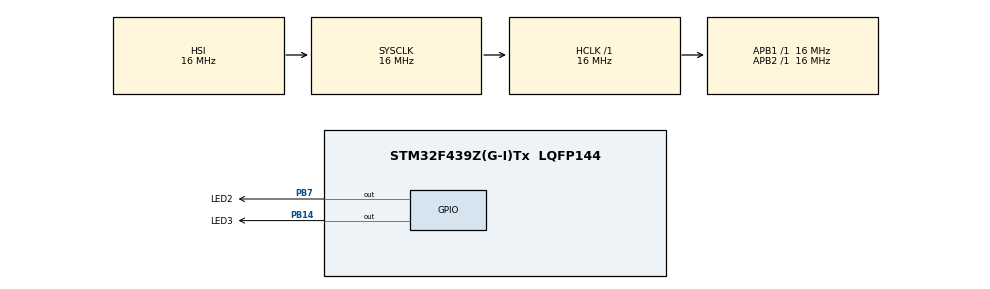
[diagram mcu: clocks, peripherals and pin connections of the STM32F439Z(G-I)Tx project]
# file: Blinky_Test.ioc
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FREERTOS.Tasks01=task01,0,128,start_task01,Default,NULL,Dynamic,NULL,NULL;task02,0,128,start_task02,Default,NULL,Dynamic,NULL,NULL
FREERTOS.configUSE_NEWLIB_REENTRANT=1
Mcu.Family=STM32F4
Mcu.Name=STM32F439Z(G-I)Tx
Mcu.Package=LQFP144
NVIC.PriorityGroup=NVIC_PRIORITYGROUP_4
NVIC.TIM1_UP_TIM10_IRQn=true\:15\:0\:false\:false\:true\:false\:false\:true\:true
NVIC.TimeBase=TIM1_UP_TIM10_IRQn
NVIC.TimeBaseIP=TIM1
PA13.Mode=Serial_Wire
PA13.Signal=SYS_JTMS-SWDIO
PA14.Mode=Serial_Wire
PA14.Signal=SYS_JTCK-SWCLK
PB14.GPIO_Label=LED3
PB14.GPIO_PuPd=GPIO_PULLDOWN
PB14.Signal=GPIO_Output
PB7.GPIO_Label=LED2
PB7.GPIO_PuPd=GPIO_PULLDOWN
PB7.Signal=GPIO_Output
PC14/OSC32_IN.Mode=LSE-External-Oscillator
PC14/OSC32_IN.Signal=RCC_OSC32_IN
PC15/OSC32_OUT.Mode=LSE-External-Oscillator
PC15/OSC32_OUT.Signal=RCC_OSC32_OUT
PH0/OSC_IN.Mode=HSE-External-Oscillator
PH0/OSC_IN.Signal=RCC_OSC_IN
PH1/OSC_OUT.Mode=HSE-External-Oscillator
PH1/OSC_OUT.Signal=RCC_OSC_OUT
ProjectManager.HeapSize=0x200
ProjectManager.StackSize=0x400
ProjectManager.TargetToolchain=STM32CubeIDE
RCC.AHBFreq_Value=16000000
RCC.APB1Freq_Value=16000000
RCC.APB2Freq_Value=16000000
RCC.CortexFreq_Value=16000000
RCC.HSE_VALUE=25000000
RCC.HSI_VALUE=16000000
RCC.SYSCLKFreq_VALUE=16000000
RCC.VCOOutputFreq_Value=192000000
VP_FREERTOS_VS_CMSIS_V1.Mode=CMSIS_V1
VP_SYS_VS_tim1.Mode=TIM1
board=custom

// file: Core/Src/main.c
/* USER CODE BEGIN Header */
/**
  ******************************************************************************
  * @file           : main.c
  * @brief          : Main program body
  ******************************************************************************
  * @attention
  *
  * Copyright (c) 2024 STMicroelectronics.
  * All rights reserved.
  *
  * This software is licensed under terms that can be found in the LICENSE file
  * in the root directory of this software component.
  * If no LICENSE file comes with this software, it is provided AS-IS.
  *
  ******************************************************************************
  */
/* USER CODE END Header */
#include "main.h"
#include "cmsis_os.h"

osThreadId task01Handle;
osThreadId task02Handle;

void SystemClock_Config(void);
static void MX_GPIO_Init(void);
void start_task01(void const * argument);
void start_task02(void const * argument);

int main(void)
{

  /* MCU Configuration--------------------------------------------------------*/

  /* Reset of all peripherals, Initializes the Flash interface and the Systick. */
  HAL_Init();

  /* Configure the system clock */
  SystemClock_Config();

  /* Initialize all configured peripherals */
  MX_GPIO_Init();

  /* Create the thread(s) */
  /* definition and creation of task01 */
  osThreadDef(task01, start_task01, osPriorityNormal, 0, 128);
  task01Handle = osThreadCreate(osThread(task01), NULL);

  /* definition and creation of task02 */
  osThreadDef(task02, start_task02, osPriorityNormal, 0, 128);
  task02Handle = osThreadCreate(osThread(task02), NULL);

  /* Start scheduler */
  osKernelStart();

  /* We should never get here as control is now taken by the scheduler */

  /* Infinite loop */
  while (1)
  {

  }
}

void SystemClock_Config(void)
{
  RCC_OscInitTypeDef RCC_OscInitStruct = {0};
  RCC_ClkInitTypeDef RCC_ClkInitStruct = {0};

  /** Configure the main internal regulator output voltage
  */
  __HAL_RCC_PWR_CLK_ENABLE();
  __HAL_PWR_VOLTAGESCALING_CONFIG(PWR_REGULATOR_VOLTAGE_SCALE3);

  /** Initializes the RCC Oscillators according to the specified parameters
  * in the RCC_OscInitTypeDef structure.
  */
  RCC_OscInitStruct.OscillatorType = RCC_OSCILLATORTYPE_HSI;
  RCC_OscInitStruct.HSIState = RCC_HSI_ON;
  RCC_OscInitStruct.HSICalibrationValue = RCC_HSICALIBRATION_DEFAULT;
  RCC_OscInitStruct.PLL.PLLState = RCC_PLL_NONE;
  if (HAL_RCC_OscConfig(&RCC_OscInitStruct) != HAL_OK)
  {
    Error_Handler();
  }

  /** Initializes the CPU, AHB and APB buses clocks
  */
  RCC_ClkInitStruct.ClockType = RCC_CLOCKTYPE_HCLK|RCC_CLOCKTYPE_SYSCLK
                              |RCC_CLOCKTYPE_PCLK1|RCC_CLOCKTYPE_PCLK2;
  RCC_ClkInitStruct.SYSCLKSource = RCC_SYSCLKSOURCE_HSI;
  RCC_ClkInitStruct.AHBCLKDivider = RCC_SYSCLK_DIV1;
  RCC_ClkInitStruct.APB1CLKDivider = RCC_HCLK_DIV1;
  RCC_ClkInitStruct.APB2CLKDivider = RCC_HCLK_DIV1;

  if (HAL_RCC_ClockConfig(&RCC_ClkInitStruct, FLASH_LATENCY_0) != HAL_OK)
  {
    Error_Handler();
  }
}

static void MX_GPIO_Init(void)
{
  GPIO_InitTypeDef GPIO_InitStruct = {0};

  /* GPIO Ports Clock Enable */
  __HAL_RCC_GPIOC_CLK_ENABLE();
  __HAL_RCC_GPIOH_CLK_ENABLE();
  __HAL_RCC_GPIOB_CLK_ENABLE();
  __HAL_RCC_GPIOA_CLK_ENABLE();

  /*Configure GPIO pin Output Level */
  HAL_GPIO_WritePin(GPIOB, LED3_Pin|LED2_Pin, GPIO_PIN_RESET);

  /*Configure GPIO pins : LED3_Pin LED2_Pin */
  GPIO_InitStruct.Pin = LED3_Pin|LED2_Pin;
  GPIO_InitStruct.Mode = GPIO_MODE_OUTPUT_PP;
  GPIO_InitStruct.Pull = GPIO_PULLDOWN;
  GPIO_InitStruct.Speed = GPIO_SPEED_FREQ_LOW;
  HAL_GPIO_Init(GPIOB, &GPIO_InitStruct);

}

void start_task01(void const * argument)
{
  /* USER CODE BEGIN 5 */
  /* Infinite loop */
  for(;;)
  {
	HAL_GPIO_TogglePin(GPIOB, GPIO_PIN_7);
	HAL_Delay(1000);
    osDelay(1);
  }
  /* USER CODE END 5 */
}

void start_task02(void const * argument)
{
  /* USER CODE BEGIN start_task02 */
  /* Infinite loop */
  for(;;)
  {
	HAL_GPIO_TogglePin(GPIOB, GPIO_PIN_14);
	HAL_Delay(1000);
    osDelay(1);
  }
  /* USER CODE END start_task02 */
}

void HAL_TIM_PeriodElapsedCallback(TIM_HandleTypeDef *htim)
{
  if (htim->Instance == TIM1) {
    HAL_IncTick();
  }
}

void Error_Handler(void)
{
  __disable_irq();
  while (1)
  {
  }
}
